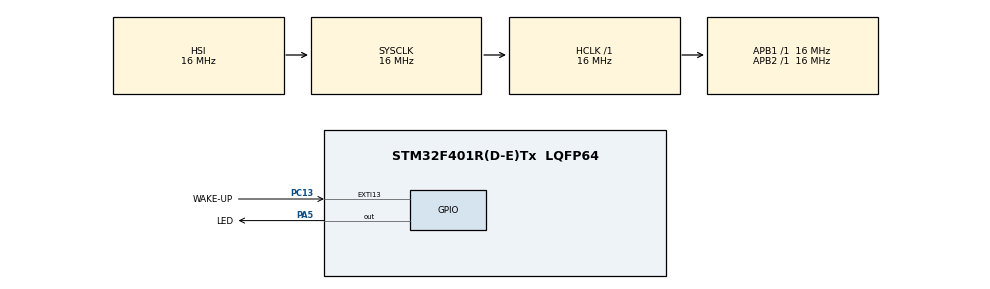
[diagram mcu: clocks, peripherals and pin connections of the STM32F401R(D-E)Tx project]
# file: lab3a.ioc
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Mcu.Family=STM32F4
Mcu.Name=STM32F401R(D-E)Tx
Mcu.Package=LQFP64
NVIC.EXTI15_10_IRQn=true\:0\:0\:false\:false\:true\:true\:true\:true
NVIC.PriorityGroup=NVIC_PRIORITYGROUP_4
PA0-WKUP.Mode=SYS_WakeUp0
PA0-WKUP.Signal=SYS_WKUP
PA5.GPIO_Label=LED
PA5.Signal=GPIO_Output
PC13-ANTI_TAMP.GPIO_Label=WAKE-UP
PC13-ANTI_TAMP.GPIO_ModeDefaultEXTI=GPIO_MODE_IT_FALLING
PC13-ANTI_TAMP.Signal=GPXTI13
ProjectManager.HeapSize=0x200
ProjectManager.StackSize=0x400
ProjectManager.TargetToolchain=STM32CubeIDE
RCC.AHBFreq_Value=16000000
RCC.APB1Freq_Value=16000000
RCC.APB2Freq_Value=16000000
RCC.CortexFreq_Value=16000000
RCC.HSE_VALUE=25000000
RCC.HSI_VALUE=16000000
RCC.LSE_VALUE=32768
RCC.SYSCLKFreq_VALUE=16000000
RCC.VCOOutputFreq_Value=192000000
board=custom

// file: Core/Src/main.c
/* USER CODE BEGIN Header */
/**
  ******************************************************************************
  * @file           : main.c
  * @brief          : Main program body
  ******************************************************************************
  * @attention
  *
  * Copyright (c) 2026 STMicroelectronics.
  * All rights reserved.
  *
  * This software is licensed under terms that can be found in the LICENSE file
  * in the root directory of this software component.
  * If no LICENSE file comes with this software, it is provided AS-IS.
  *
  ******************************************************************************
  */
/* USER CODE END Header */
#include "main.h"

/* USER CODE BEGIN PV */
volatile uint32_t g_wakeCount = 0;
volatile uint8_t  g_doBlink = 0;
volatile uint8_t  g_requestStandby = 0;
/* USER CODE END PV */

void SystemClock_Config(void);
static void MX_GPIO_Init(void);
static void BlinkTimes(uint32_t n);
static void BlinkRestartPattern(void);
static void BlinkStandbyPattern(void);
static void EnterStandbyMode(void);

/* USER CODE BEGIN 0 */

/* Blink LED n times */
static void BlinkTimes(uint32_t n)
{
  uint32_t i;

  for (i = 0; i < n; i++)
  {
    HAL_GPIO_WritePin(LED_GPIO_Port, LED_Pin, GPIO_PIN_SET);
    HAL_Delay(120);
    HAL_GPIO_WritePin(LED_GPIO_Port, LED_Pin, GPIO_PIN_RESET);
    HAL_Delay(120);
  }

  HAL_Delay(500);
}

/* 3 long blinks = restarted from standby */
static void BlinkRestartPattern(void)
{
  uint32_t i;

  for (i = 0; i < 3; i++)
  {
    HAL_GPIO_WritePin(LED_GPIO_Port, LED_Pin, GPIO_PIN_SET);
    HAL_Delay(500);
    HAL_GPIO_WritePin(LED_GPIO_Port, LED_Pin, GPIO_PIN_RESET);
    HAL_Delay(500);
  }

  HAL_Delay(500);
}

/* short-short-long = entering standby */
static void BlinkStandbyPattern(void)
{
  HAL_GPIO_WritePin(LED_GPIO_Port, LED_Pin, GPIO_PIN_SET);
  HAL_Delay(100);
  HAL_GPIO_WritePin(LED_GPIO_Port, LED_Pin, GPIO_PIN_RESET);
  HAL_Delay(100);

  HAL_GPIO_WritePin(LED_GPIO_Port, LED_Pin, GPIO_PIN_SET);
  HAL_Delay(100);
  HAL_GPIO_WritePin(LED_GPIO_Port, LED_Pin, GPIO_PIN_RESET);
  HAL_Delay(500);

  HAL_GPIO_WritePin(LED_GPIO_Port, LED_Pin, GPIO_PIN_SET);
  HAL_Delay(100);
  HAL_GPIO_WritePin(LED_GPIO_Port, LED_Pin, GPIO_PIN_RESET);
  HAL_Delay(100);
  HAL_GPIO_WritePin(LED_GPIO_Port, LED_Pin, GPIO_PIN_SET);
  HAL_Delay(100);
  HAL_GPIO_WritePin(LED_GPIO_Port, LED_Pin, GPIO_PIN_RESET);
  HAL_Delay(100);
  HAL_GPIO_WritePin(LED_GPIO_Port, LED_Pin, GPIO_PIN_SET);
  HAL_Delay(300);
  HAL_GPIO_WritePin(LED_GPIO_Port, LED_Pin, GPIO_PIN_RESET);
  HAL_Delay(200);
}

static void EnterStandbyMode(void)
{
  /* Make sure LED is off before sleep */
  HAL_GPIO_WritePin(LED_GPIO_Port, LED_Pin, GPIO_PIN_RESET);

  /* Clear standby/wakeup flags before entering standby */
  __HAL_PWR_CLEAR_FLAG(PWR_FLAG_WU);
  __HAL_PWR_CLEAR_FLAG(PWR_FLAG_SB);

  /* PA0 = WakeUp Pin 1 */
  HAL_PWR_EnableWakeUpPin(PWR_WAKEUP_PIN1);

  HAL_PWR_EnterSTANDBYMode();

  /* never returns */
}

void HAL_GPIO_EXTI_Callback(uint16_t GPIO_Pin)
{
  uint32_t now = HAL_GetTick();

  if (GPIO_Pin == WAKE_UP_Pin)   /* Onboard button: usually PC13 */
  {
    static uint32_t lastTick13 = 0;

    if ((now - lastTick13) < 200)
    {
      return;
    }
    lastTick13 = now;

    g_wakeCount++;
    g_requestStandby = 1;
  }
}

/* USER CODE END 0 */

int main(void)
{

  /* MCU Configuration--------------------------------------------------------*/

  /* Reset of all peripherals, Initializes the Flash interface and the Systick. */
  HAL_Init();

  /* Configure the system clock */
  SystemClock_Config();

  /* Initialize all configured peripherals */
  MX_GPIO_Init();

  /* USER CODE BEGIN 2 */
  /* Detect if we restarted from STANDBY wake-up */
  if (__HAL_PWR_GET_FLAG(PWR_FLAG_SB) != RESET)
  {
    __HAL_PWR_CLEAR_FLAG(PWR_FLAG_SB);
    __HAL_PWR_CLEAR_FLAG(PWR_FLAG_WU);

    g_doBlink = 1;
    BlinkRestartPattern();
  }
  else
  {
    BlinkTimes(5);
  }
  /* USER CODE END 2 */

  /* Infinite loop */
  /* USER CODE BEGIN WHILE */
  while (1)
  {
    if (g_doBlink)
    {
      g_doBlink = 0;
      BlinkTimes(g_wakeCount);
    }

    if (g_requestStandby)
    {
      g_requestStandby = 0;

      BlinkStandbyPattern();
      HAL_Delay(150);

      EnterStandbyMode();
    }

    /* USER CODE END WHILE */

  }
}

void SystemClock_Config(void)
{
  RCC_OscInitTypeDef RCC_OscInitStruct = {0};
  RCC_ClkInitTypeDef RCC_ClkInitStruct = {0};

  /** Configure the main internal regulator output voltage
  */
  __HAL_RCC_PWR_CLK_ENABLE();
  __HAL_PWR_VOLTAGESCALING_CONFIG(PWR_REGULATOR_VOLTAGE_SCALE2);

  /** Initializes the RCC Oscillators according to the specified parameters
  * in the RCC_OscInitTypeDef structure.
  */
  RCC_OscInitStruct.OscillatorType = RCC_OSCILLATORTYPE_HSI;
  RCC_OscInitStruct.HSIState = RCC_HSI_ON;
  RCC_OscInitStruct.HSICalibrationValue = RCC_HSICALIBRATION_DEFAULT;
  RCC_OscInitStruct.PLL.PLLState = RCC_PLL_NONE;
  if (HAL_RCC_OscConfig(&RCC_OscInitStruct) != HAL_OK)
  {
    Error_Handler();
  }

  /** Initializes the CPU, AHB and APB buses clocks
  */
  RCC_ClkInitStruct.ClockType = RCC_CLOCKTYPE_HCLK | RCC_CLOCKTYPE_SYSCLK
                              | RCC_CLOCKTYPE_PCLK1 | RCC_CLOCKTYPE_PCLK2;
  RCC_ClkInitStruct.SYSCLKSource = RCC_SYSCLKSOURCE_HSI;
  RCC_ClkInitStruct.AHBCLKDivider = RCC_SYSCLK_DIV1;
  RCC_ClkInitStruct.APB1CLKDivider = RCC_HCLK_DIV1;
  RCC_ClkInitStruct.APB2CLKDivider = RCC_HCLK_DIV1;

  if (HAL_RCC_ClockConfig(&RCC_ClkInitStruct, FLASH_LATENCY_0) != HAL_OK)
  {
    Error_Handler();
  }
}

static void MX_GPIO_Init(void)
{
  GPIO_InitTypeDef GPIO_InitStruct = {0};

  /* GPIO Ports Clock Enable */
  __HAL_RCC_GPIOC_CLK_ENABLE();
  __HAL_RCC_GPIOA_CLK_ENABLE();

  /* Configure LED output level */
  HAL_GPIO_WritePin(LED_GPIO_Port, LED_Pin, GPIO_PIN_RESET);

  /* Configure onboard button as EXTI
     WAKE_UP_Pin is typically PC13 on Nucleo boards */
  GPIO_InitStruct.Pin = WAKE_UP_Pin;
  GPIO_InitStruct.Mode = GPIO_MODE_IT_FALLING;
  GPIO_InitStruct.Pull = GPIO_NOPULL;
  HAL_GPIO_Init(WAKE_UP_GPIO_Port, &GPIO_InitStruct);

  /* Configure LED pin */
  GPIO_InitStruct.Pin = LED_Pin;
  GPIO_InitStruct.Mode = GPIO_MODE_OUTPUT_PP;
  GPIO_InitStruct.Pull = GPIO_NOPULL;
  GPIO_InitStruct.Speed = GPIO_SPEED_FREQ_LOW;
  HAL_GPIO_Init(LED_GPIO_Port, &GPIO_InitStruct);

  /* EXTI interrupt init for onboard button */
  HAL_NVIC_SetPriority(EXTI15_10_IRQn, 0, 0);
  HAL_NVIC_EnableIRQ(EXTI15_10_IRQn);

}

void Error_Handler(void)
{
  __disable_irq();
  while (1)
  {
  }
}
